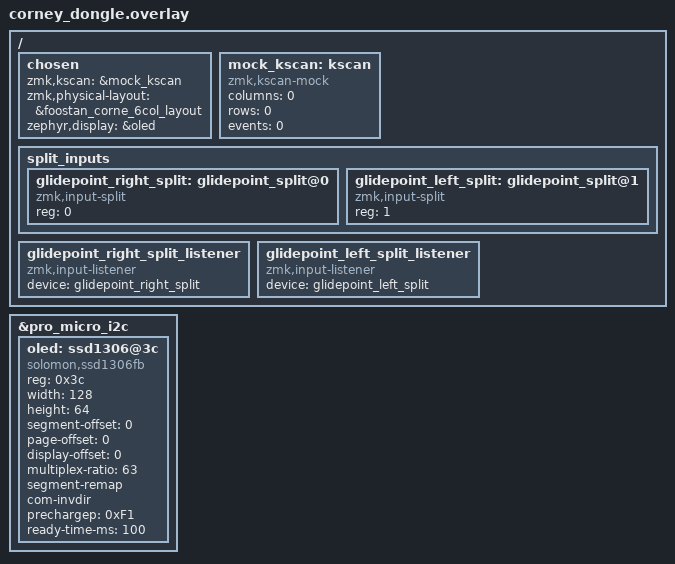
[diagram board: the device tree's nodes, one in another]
#include "corney_layouts.dtsi"

/ {
    chosen {
        zmk,kscan = &mock_kscan;
        zmk,physical-layout = &foostan_corne_6col_layout;
        zephyr,display = &oled;
    };

    mock_kscan: kscan {
        compatible = "zmk,kscan-mock";
        columns = <0>;
        rows = <0>;
        events = <0>;
    };

    split_inputs {
        #address-cells = <1>;
        #size-cells = <0>;

        glidepoint_right_split: glidepoint_split@0 {
            compatible = "zmk,input-split";
            reg = <0>;
        };

        glidepoint_left_split: glidepoint_split@1 {
            compatible = "zmk,input-split";
            reg = <1>;
        };
    };

    glidepoint_right_split_listener {
        compatible = "zmk,input-listener";
        device = <&glidepoint_right_split>;
    };

    glidepoint_left_split_listener {
        compatible = "zmk,input-listener";
        device = <&glidepoint_left_split>;
    };
};

&pro_micro_i2c {
    status = "okay";

    oled: ssd1306@3c {
        compatible = "solomon,ssd1306fb";
        reg = <0x3c>;
        width = <128>;
        height = <64>;

        segment-offset = <0>;
        page-offset = <0>;
        display-offset = <0>;
        multiplex-ratio = <63>;

        segment-remap;
        com-invdir;

        prechargep = <0xF1>;
        ready-time-ms = <100>;
    };
};
